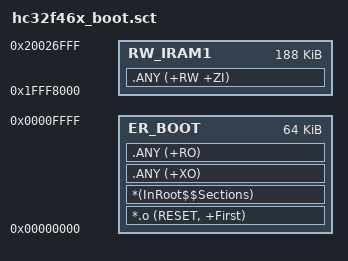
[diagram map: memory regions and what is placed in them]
; *************************************************************
; *** Scatter-Loading Description File generated by uVision ***
; *************************************************************

LR_IROM1 0x00000000 0x00010000  {    ; Total Flash 512K
  ; Bootloader Section
  ER_BOOT 0x00000000 0x00010000  {  ; 64K Bootloader
    *.o (RESET, +First)
    *(InRoot$$Sections)
    .ANY (+XO)
    .ANY (+RO)
  }

  ; RAM Section
  RW_IRAM1 0x1FFF8000 0x0002F000  {  ; RW data
   .ANY (+RW +ZI)
  }
}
